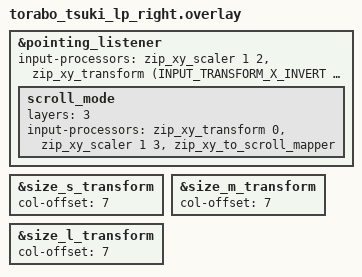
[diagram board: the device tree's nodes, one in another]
#include "torabo_tsuki_lp.dtsi"
#include <input/processors.dtsi>
#include <dt-bindings/zmk/input_transform.h>

&pointing_listener {
    /* ベース設定：通常のカーソル移動の速度を 1/2 にし、反転を適用 */
    input-processors = 
        <&zip_xy_scaler 1 2>, 
        <&zip_xy_transform (INPUT_TRANSFORM_X_INVERT | INPUT_TRANSFORM_Y_INVERT)>;

    /* Layer 3 の時だけ設定を上書き（スクロールモード） */
    scroll_mode {
        layers = <3>;
        input-processors = 
            <&zip_xy_transform 0>, // 操作を反転
            // <&zip_xy_transform (INPUT_TRANSFORM_X_INVERT | INPUT_TRANSFORM_Y_INVERT)>, // 元のコード
            <&zip_xy_scaler 1 3>, // スクロール感度は 1/3
            <&zip_xy_to_scroll_mapper>; // 移動をスクロールに変換
    };
};

/* キーマトリックス・オフセット（既存のまま） */
&size_s_transform { col-offset = <7>; };
&size_m_transform { col-offset = <7>; };
&size_l_transform { col-offset = <7>; };
